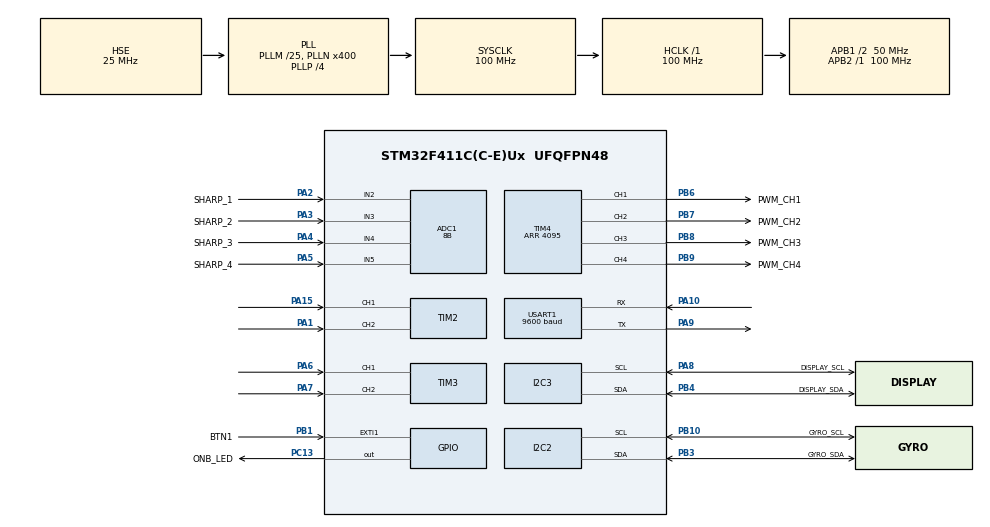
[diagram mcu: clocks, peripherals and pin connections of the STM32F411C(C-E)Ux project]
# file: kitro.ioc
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ADC1.Channel-1\#ChannelRegularConversion=ADC_CHANNEL_2
ADC1.ContinuousConvMode=DISABLE
ADC1.DMAContinuousRequests=ENABLE
ADC1.NbrOfConversion=1
ADC1.NbrOfConversionFlag=1
ADC1.Rank-1\#ChannelRegularConversion=1
ADC1.Resolution=ADC_RESOLUTION_8B
ADC1.SamplingTime-1\#ChannelRegularConversion=ADC_SAMPLETIME_3CYCLES
ADC1.master=1
Dma.ADC1.0.Direction=DMA_PERIPH_TO_MEMORY
Dma.ADC1.0.FIFOMode=DMA_FIFOMODE_DISABLE
Dma.ADC1.0.Instance=DMA2_Stream0
Dma.ADC1.0.MemDataAlignment=DMA_MDATAALIGN_HALFWORD
Dma.ADC1.0.MemInc=DMA_MINC_ENABLE
Dma.ADC1.0.Mode=DMA_CIRCULAR
Dma.ADC1.0.PeriphDataAlignment=DMA_PDATAALIGN_HALFWORD
Dma.ADC1.0.PeriphInc=DMA_PINC_DISABLE
Dma.ADC1.0.Priority=DMA_PRIORITY_LOW
Dma.Request0=ADC1
I2C3.I2C_Mode=I2C_Fast
Mcu.Family=STM32F4
Mcu.Name=STM32F411C(C-E)Ux
Mcu.Package=UFQFPN48
NVIC.DMA2_Stream0_IRQn=true\:0\:0\:false\:false\:true\:false\:true\:true
NVIC.EXTI1_IRQn=true\:0\:0\:false\:false\:true\:true\:true\:true
NVIC.PriorityGroup=NVIC_PRIORITYGROUP_4
NVIC.TIM1_TRG_COM_TIM11_IRQn=true\:0\:0\:false\:false\:true\:true\:true\:true
NVIC.TIM1_UP_TIM10_IRQn=true\:0\:0\:false\:false\:true\:true\:true\:true
NVIC.TIM5_IRQn=true\:0\:0\:false\:false\:true\:true\:true\:true
PA1.Signal=S_TIM2_CH2
PA10.Mode=Asynchronous
PA10.Signal=USART1_RX
PA15.Signal=S_TIM2_CH1_ETR
PA2.GPIO_Label=SHARP_1
PA2.Signal=ADCx_IN2
PA3.GPIO_Label=SHARP_2
PA3.Signal=ADCx_IN3
PA4.GPIO_Label=SHARP_3
PA4.Signal=ADCx_IN4
PA5.GPIO_Label=SHARP_4
PA5.Signal=ADCx_IN5
PA6.Signal=S_TIM3_CH1
PA7.Signal=S_TIM3_CH2
PA8.GPIO_Label=DISPLAY_SCL
PA8.Mode=I2C
PA8.Signal=I2C3_SCL
PA9.Mode=Asynchronous
PA9.Signal=USART1_TX
PB1.GPIO_Label=BTN1
PB1.GPIO_ModeDefaultEXTI=GPIO_MODE_IT_FALLING
PB1.GPIO_PuPd=GPIO_PULLDOWN
PB1.Signal=GPXTI1
PB10.GPIO_Label=GYRO_SCL
PB10.Mode=I2C
PB10.Signal=I2C2_SCL
PB3.GPIO_Label=GYRO_SDA
PB3.Mode=I2C
PB3.Signal=I2C2_SDA
PB4.GPIO_Label=DISPLAY_SDA
PB4.Mode=I2C
PB4.Signal=I2C3_SDA
PB6.GPIO_Label=PWM_CH1
PB6.Signal=S_TIM4_CH1
PB7.GPIO_Label=PWM_CH2
PB7.Signal=S_TIM4_CH2
PB8.GPIO_Label=PWM_CH3
PB8.Signal=S_TIM4_CH3
PB9.GPIO_Label=PWM_CH4
PB9.Signal=S_TIM4_CH4
PC13-ANTI_TAMP.GPIO_Label=ONB_LED
PC13-ANTI_TAMP.GPIO_PuPd=GPIO_NOPULL
PC13-ANTI_TAMP.Signal=GPIO_Output
PH0\ -\ OSC_IN.Mode=HSE-External-Oscillator
PH0\ -\ OSC_IN.Signal=RCC_OSC_IN
PH1\ -\ OSC_OUT.Mode=HSE-External-Oscillator
PH1\ -\ OSC_OUT.Signal=RCC_OSC_OUT
ProjectManager.HeapSize=0x200
ProjectManager.StackSize=0x400
ProjectManager.TargetToolchain=STM32CubeIDE
RCC.48MHZClocksFreq_Value=100000000
RCC.AHBFreq_Value=100000000
RCC.APB1CLKDivider=RCC_HCLK_DIV2
RCC.APB1Freq_Value=50000000
RCC.APB1TimFreq_Value=100000000
RCC.APB2Freq_Value=100000000
RCC.APB2TimFreq_Value=100000000
RCC.CortexFreq_Value=100000000
RCC.HCLKFreq_Value=100000000
RCC.HSE_VALUE=25000000
RCC.HSI_VALUE=16000000
RCC.LSE_VALUE=32768
RCC.PLLM=25
RCC.PLLN=400
RCC.PLLP=RCC_PLLP_DIV4
RCC.PLLSourceVirtual=RCC_PLLSOURCE_HSE
RCC.SYSCLKFreq_VALUE=100000000
RCC.SYSCLKSource=RCC_SYSCLKSOURCE_PLLCLK
RCC.VCOOutputFreq_Value=400000000
SH.ADCx_IN2.0=ADC1_IN2,IN2
SH.ADCx_IN3.0=ADC1_IN3,IN3
SH.ADCx_IN4.0=ADC1_IN4,IN4
SH.ADCx_IN5.0=ADC1_IN5,IN5
SH.S_TIM2_CH1_ETR.0=TIM2_CH1,Encoder_Interface
SH.S_TIM2_CH2.0=TIM2_CH2,Encoder_Interface
SH.S_TIM3_CH1.0=TIM3_CH1,Encoder_Interface
SH.S_TIM3_CH2.0=TIM3_CH2,Encoder_Interface
SH.S_TIM4_CH1.0=TIM4_CH1,PWM Generation1 CH1
SH.S_TIM4_CH2.0=TIM4_CH2,PWM Generation2 CH2
SH.S_TIM4_CH3.0=TIM4_CH3,PWM Generation3 CH3
SH.S_TIM4_CH4.0=TIM4_CH4,PWM Generation4 CH4
TIM10.Prescaler=15
TIM11.Prescaler=127
TIM4.Channel-PWM\ Generation1\ CH1=TIM_CHANNEL_1
TIM4.Channel-PWM\ Generation2\ CH2=TIM_CHANNEL_2
TIM4.Channel-PWM\ Generation3\ CH3=TIM_CHANNEL_3
TIM4.Channel-PWM\ Generation4\ CH4=TIM_CHANNEL_4
TIM4.Period=4095
USART1.BaudRate=9600
USART1.VirtualMode=VM_ASYNC
VP_ADC1_Vbat_Input.Mode=IN-Vbat
VP_TIM10_VS_ClockSourceINT.Mode=Enable_Timer
VP_TIM11_VS_ClockSourceINT.Mode=Enable_Timer
VP_TIM1_VS_ClockSourceINT.Mode=Internal
VP_TIM5_VS_ClockSourceINT.Mode=Internal
board=custom

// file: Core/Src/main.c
/* USER CODE BEGIN Header */
/**
 ******************************************************************************
 * @file           : main.c
 * @brief          : Main program body
 ******************************************************************************
 * @attention
 *
 * Copyright (c) 2024 STMicroelectronics.
 * All rights reserved.
 *
 * This software is licensed under terms that can be found in the LICENSE file
 * in the root directory of this software component.
 * If no LICENSE file comes with this software, it is provided AS-IS.
 *
 ******************************************************************************
 */
/* USER CODE END Header */
#include "main.h"

ADC_HandleTypeDef hadc1;
DMA_HandleTypeDef hdma_adc1;

I2C_HandleTypeDef hi2c2;
I2C_HandleTypeDef hi2c3;

TIM_HandleTypeDef htim1;
TIM_HandleTypeDef htim2;
TIM_HandleTypeDef htim3;
TIM_HandleTypeDef htim4;
TIM_HandleTypeDef htim5;
TIM_HandleTypeDef htim10;
TIM_HandleTypeDef htim11;

UART_HandleTypeDef huart1;

void SystemClock_Config(void);
static void MX_GPIO_Init(void);
static void MX_DMA_Init(void);
static void MX_ADC1_Init(void);
static void MX_I2C2_Init(void);
static void MX_I2C3_Init(void);
static void MX_TIM4_Init(void);
static void MX_USART1_UART_Init(void);
static void MX_TIM2_Init(void);
static void MX_TIM3_Init(void);
static void MX_TIM10_Init(void);
static void MX_TIM1_Init(void);
static void MX_TIM5_Init(void);
static void MX_TIM11_Init(void);
/* USER CODE BEGIN PFP */
//#define PUTCHAR_PROTOTYPE int __io_putchar(int ch)
/* USER CODE END PFP */

/* USER CODE BEGIN 0 */
int _write(int fd, char *ptr, int len) {
	HAL_UART_Transmit(&huart1, (uint8_t*) ptr, len, HAL_MAX_DELAY);
	return len;
}
/**
 * @brief  Retargets the C library printf function to the USART.
 *   None
 * @retval None
 */
//PUTCHAR_PROTOTYPE
//{
//  /* Place your implementation of fputc here */
//  /* e.g. write a character to the USART1 and Loop until the end of transmission */
//  HAL_UART_Transmit(&huart1, (uint8_t *)&ch, 1, 0xFFFF);
//
//  return ch;
//}
/* USER CODE END 0 */

int main(void)
{

  /* MCU Configuration--------------------------------------------------------*/

  /* Reset of all peripherals, Initializes the Flash interface and the Systick. */
  HAL_Init();

  /* Configure the system clock */
  SystemClock_Config();

  /* Initialize all configured peripherals */
  MX_GPIO_Init();
  MX_DMA_Init();
  MX_ADC1_Init();
  MX_I2C2_Init();
  MX_I2C3_Init();
  MX_TIM4_Init();
  MX_USART1_UART_Init();
  MX_TIM2_Init();
  MX_TIM3_Init();
  MX_TIM10_Init();
  MX_TIM1_Init();
  MX_TIM5_Init();
  MX_TIM11_Init();

  /* Infinite loop */
  /* USER CODE BEGIN WHILE */
	// transfer main to greymatter function in entry.cpp
	greymatter();
	while (1) {

    /* USER CODE END WHILE */

	}
}

void SystemClock_Config(void)
{
  RCC_OscInitTypeDef RCC_OscInitStruct = {0};
  RCC_ClkInitTypeDef RCC_ClkInitStruct = {0};

  /** Configure the main internal regulator output voltage
  */
  __HAL_RCC_PWR_CLK_ENABLE();
  __HAL_PWR_VOLTAGESCALING_CONFIG(PWR_REGULATOR_VOLTAGE_SCALE1);

  /** Initializes the RCC Oscillators according to the specified parameters
  * in the RCC_OscInitTypeDef structure.
  */
  RCC_OscInitStruct.OscillatorType = RCC_OSCILLATORTYPE_HSE;
  RCC_OscInitStruct.HSEState = RCC_HSE_ON;
  RCC_OscInitStruct.PLL.PLLState = RCC_PLL_ON;
  RCC_OscInitStruct.PLL.PLLSource = RCC_PLLSOURCE_HSE;
  RCC_OscInitStruct.PLL.PLLM = 25;
  RCC_OscInitStruct.PLL.PLLN = 400;
  RCC_OscInitStruct.PLL.PLLP = RCC_PLLP_DIV4;
  RCC_OscInitStruct.PLL.PLLQ = 4;
  if (HAL_RCC_OscConfig(&RCC_OscInitStruct) != HAL_OK)
  {
    Error_Handler();
  }

  /** Initializes the CPU, AHB and APB buses clocks
  */
  RCC_ClkInitStruct.ClockType = RCC_CLOCKTYPE_HCLK|RCC_CLOCKTYPE_SYSCLK
                              |RCC_CLOCKTYPE_PCLK1|RCC_CLOCKTYPE_PCLK2;
  RCC_ClkInitStruct.SYSCLKSource = RCC_SYSCLKSOURCE_PLLCLK;
  RCC_ClkInitStruct.AHBCLKDivider = RCC_SYSCLK_DIV1;
  RCC_ClkInitStruct.APB1CLKDivider = RCC_HCLK_DIV2;
  RCC_ClkInitStruct.APB2CLKDivider = RCC_HCLK_DIV1;

  if (HAL_RCC_ClockConfig(&RCC_ClkInitStruct, FLASH_LATENCY_3) != HAL_OK)
  {
    Error_Handler();
  }
}

static void MX_ADC1_Init(void)
{

  ADC_ChannelConfTypeDef sConfig = {0};

  /** Configure the global features of the ADC (Clock, Resolution, Data Alignment and number of conversion)
  */
  hadc1.Instance = ADC1;
  hadc1.Init.ClockPrescaler = ADC_CLOCK_SYNC_PCLK_DIV4;
  hadc1.Init.Resolution = ADC_RESOLUTION_8B;
  hadc1.Init.ScanConvMode = DISABLE;
  hadc1.Init.ContinuousConvMode = DISABLE;
  hadc1.Init.DiscontinuousConvMode = DISABLE;
  hadc1.Init.ExternalTrigConvEdge = ADC_EXTERNALTRIGCONVEDGE_NONE;
  hadc1.Init.ExternalTrigConv = ADC_SOFTWARE_START;
  hadc1.Init.DataAlign = ADC_DATAALIGN_RIGHT;
  hadc1.Init.NbrOfConversion = 1;
  hadc1.Init.DMAContinuousRequests = ENABLE;
  hadc1.Init.EOCSelection = ADC_EOC_SINGLE_CONV;
  if (HAL_ADC_Init(&hadc1) != HAL_OK)
  {
    Error_Handler();
  }

  /** Configure for the selected ADC regular channel its corresponding rank in the sequencer and its sample time.
  */
  sConfig.Channel = ADC_CHANNEL_2;
  sConfig.Rank = 1;
  sConfig.SamplingTime = ADC_SAMPLETIME_3CYCLES;
  if (HAL_ADC_ConfigChannel(&hadc1, &sConfig) != HAL_OK)
  {
    Error_Handler();
  }

}

static void MX_I2C2_Init(void)
{

  hi2c2.Instance = I2C2;
  hi2c2.Init.ClockSpeed = 100000;
  hi2c2.Init.DutyCycle = I2C_DUTYCYCLE_2;
  hi2c2.Init.OwnAddress1 = 0;
  hi2c2.Init.AddressingMode = I2C_ADDRESSINGMODE_7BIT;
  hi2c2.Init.DualAddressMode = I2C_DUALADDRESS_DISABLE;
  hi2c2.Init.OwnAddress2 = 0;
  hi2c2.Init.GeneralCallMode = I2C_GENERALCALL_DISABLE;
  hi2c2.Init.NoStretchMode = I2C_NOSTRETCH_DISABLE;
  if (HAL_I2C_Init(&hi2c2) != HAL_OK)
  {
    Error_Handler();
  }

}

static void MX_I2C3_Init(void)
{

  hi2c3.Instance = I2C3;
  hi2c3.Init.ClockSpeed = 400000;
  hi2c3.Init.DutyCycle = I2C_DUTYCYCLE_2;
  hi2c3.Init.OwnAddress1 = 0;
  hi2c3.Init.AddressingMode = I2C_ADDRESSINGMODE_7BIT;
  hi2c3.Init.DualAddressMode = I2C_DUALADDRESS_DISABLE;
  hi2c3.Init.OwnAddress2 = 0;
  hi2c3.Init.GeneralCallMode = I2C_GENERALCALL_DISABLE;
  hi2c3.Init.NoStretchMode = I2C_NOSTRETCH_DISABLE;
  if (HAL_I2C_Init(&hi2c3) != HAL_OK)
  {
    Error_Handler();
  }

}

static void MX_TIM1_Init(void)
{

  TIM_ClockConfigTypeDef sClockSourceConfig = {0};
  TIM_MasterConfigTypeDef sMasterConfig = {0};

  htim1.Instance = TIM1;
  htim1.Init.Prescaler = 0;
  htim1.Init.CounterMode = TIM_COUNTERMODE_UP;
  htim1.Init.Period = 65535;
  htim1.Init.ClockDivision = TIM_CLOCKDIVISION_DIV1;
  htim1.Init.RepetitionCounter = 0;
  htim1.Init.AutoReloadPreload = TIM_AUTORELOAD_PRELOAD_DISABLE;
  if (HAL_TIM_Base_Init(&htim1) != HAL_OK)
  {
    Error_Handler();
  }
  sClockSourceConfig.ClockSource = TIM_CLOCKSOURCE_INTERNAL;
  if (HAL_TIM_ConfigClockSource(&htim1, &sClockSourceConfig) != HAL_OK)
  {
    Error_Handler();
  }
  sMasterConfig.MasterOutputTrigger = TIM_TRGO_RESET;
  sMasterConfig.MasterSlaveMode = TIM_MASTERSLAVEMODE_DISABLE;
  if (HAL_TIMEx_MasterConfigSynchronization(&htim1, &sMasterConfig) != HAL_OK)
  {
    Error_Handler();
  }

}

static void MX_TIM2_Init(void)
{

  TIM_Encoder_InitTypeDef sConfig = {0};
  TIM_MasterConfigTypeDef sMasterConfig = {0};

  htim2.Instance = TIM2;
  htim2.Init.Prescaler = 0;
  htim2.Init.CounterMode = TIM_COUNTERMODE_UP;
  htim2.Init.Period = 4294967295;
  htim2.Init.ClockDivision = TIM_CLOCKDIVISION_DIV1;
  htim2.Init.AutoReloadPreload = TIM_AUTORELOAD_PRELOAD_DISABLE;
  sConfig.EncoderMode = TIM_ENCODERMODE_TI1;
  sConfig.IC1Polarity = TIM_ICPOLARITY_RISING;
  sConfig.IC1Selection = TIM_ICSELECTION_DIRECTTI;
  sConfig.IC1Prescaler = TIM_ICPSC_DIV1;
  sConfig.IC1Filter = 0;
  sConfig.IC2Polarity = TIM_ICPOLARITY_RISING;
  sConfig.IC2Selection = TIM_ICSELECTION_DIRECTTI;
  sConfig.IC2Prescaler = TIM_ICPSC_DIV1;
  sConfig.IC2Filter = 0;
  if (HAL_TIM_Encoder_Init(&htim2, &sConfig) != HAL_OK)
  {
    Error_Handler();
  }
  sMasterConfig.MasterOutputTrigger = TIM_TRGO_RESET;
  sMasterConfig.MasterSlaveMode = TIM_MASTERSLAVEMODE_DISABLE;
  if (HAL_TIMEx_MasterConfigSynchronization(&htim2, &sMasterConfig) != HAL_OK)
  {
    Error_Handler();
  }

}

static void MX_TIM3_Init(void)
{

  TIM_Encoder_InitTypeDef sConfig = {0};
  TIM_MasterConfigTypeDef sMasterConfig = {0};

  htim3.Instance = TIM3;
  htim3.Init.Prescaler = 0;
  htim3.Init.CounterMode = TIM_COUNTERMODE_UP;
  htim3.Init.Period = 65535;
  htim3.Init.ClockDivision = TIM_CLOCKDIVISION_DIV1;
  htim3.Init.AutoReloadPreload = TIM_AUTORELOAD_PRELOAD_DISABLE;
  sConfig.EncoderMode = TIM_ENCODERMODE_TI1;
  sConfig.IC1Polarity = TIM_ICPOLARITY_RISING;
  sConfig.IC1Selection = TIM_ICSELECTION_DIRECTTI;
  sConfig.IC1Prescaler = TIM_ICPSC_DIV1;
  sConfig.IC1Filter = 0;
  sConfig.IC2Polarity = TIM_ICPOLARITY_RISING;
  sConfig.IC2Selection = TIM_ICSELECTION_DIRECTTI;
  sConfig.IC2Prescaler = TIM_ICPSC_DIV1;
  sConfig.IC2Filter = 0;
  if (HAL_TIM_Encoder_Init(&htim3, &sConfig) != HAL_OK)
  {
    Error_Handler();
  }
  sMasterConfig.MasterOutputTrigger = TIM_TRGO_RESET;
  sMasterConfig.MasterSlaveMode = TIM_MASTERSLAVEMODE_DISABLE;
  if (HAL_TIMEx_MasterConfigSynchronization(&htim3, &sMasterConfig) != HAL_OK)
  {
    Error_Handler();
  }

}

static void MX_TIM4_Init(void)
{

  TIM_MasterConfigTypeDef sMasterConfig = {0};
  TIM_OC_InitTypeDef sConfigOC = {0};

  htim4.Instance = TIM4;
  htim4.Init.Prescaler = 0;
  htim4.Init.CounterMode = TIM_COUNTERMODE_UP;
  htim4.Init.Period = 4095;
  htim4.Init.ClockDivision = TIM_CLOCKDIVISION_DIV1;
  htim4.Init.AutoReloadPreload = TIM_AUTORELOAD_PRELOAD_DISABLE;
  if (HAL_TIM_PWM_Init(&htim4) != HAL_OK)
  {
    Error_Handler();
  }
  sMasterConfig.MasterOutputTrigger = TIM_TRGO_RESET;
  sMasterConfig.MasterSlaveMode = TIM_MASTERSLAVEMODE_DISABLE;
  if (HAL_TIMEx_MasterConfigSynchronization(&htim4, &sMasterConfig) != HAL_OK)
  {
    Error_Handler();
  }
  sConfigOC.OCMode = TIM_OCMODE_PWM1;
  sConfigOC.Pulse = 0;
  sConfigOC.OCPolarity = TIM_OCPOLARITY_HIGH;
  sConfigOC.OCFastMode = TIM_OCFAST_DISABLE;
  if (HAL_TIM_PWM_ConfigChannel(&htim4, &sConfigOC, TIM_CHANNEL_1) != HAL_OK)
  {
    Error_Handler();
  }
  if (HAL_TIM_PWM_ConfigChannel(&htim4, &sConfigOC, TIM_CHANNEL_2) != HAL_OK)
  {
    Error_Handler();
  }
  if (HAL_TIM_PWM_ConfigChannel(&htim4, &sConfigOC, TIM_CHANNEL_3) != HAL_OK)
  {
    Error_Handler();
  }
  if (HAL_TIM_PWM_ConfigChannel(&htim4, &sConfigOC, TIM_CHANNEL_4) != HAL_OK)
  {
    Error_Handler();
  }
  HAL_TIM_MspPostInit(&htim4);

}

static void MX_TIM5_Init(void)
{

  TIM_ClockConfigTypeDef sClockSourceConfig = {0};
  TIM_MasterConfigTypeDef sMasterConfig = {0};

  htim5.Instance = TIM5;
  htim5.Init.Prescaler = 0;
  htim5.Init.CounterMode = TIM_COUNTERMODE_UP;
  htim5.Init.Period = 4294967295;
  htim5.Init.ClockDivision = TIM_CLOCKDIVISION_DIV1;
  htim5.Init.AutoReloadPreload = TIM_AUTORELOAD_PRELOAD_DISABLE;
  if (HAL_TIM_Base_Init(&htim5) != HAL_OK)
  {
    Error_Handler();
  }
  sClockSourceConfig.ClockSource = TIM_CLOCKSOURCE_INTERNAL;
  if (HAL_TIM_ConfigClockSource(&htim5, &sClockSourceConfig) != HAL_OK)
  {
    Error_Handler();
  }
  sMasterConfig.MasterOutputTrigger = TIM_TRGO_RESET;
  sMasterConfig.MasterSlaveMode = TIM_MASTERSLAVEMODE_DISABLE;
  if (HAL_TIMEx_MasterConfigSynchronization(&htim5, &sMasterConfig) != HAL_OK)
  {
    Error_Handler();
  }

}

static void MX_TIM10_Init(void)
{

  htim10.Instance = TIM10;
  htim10.Init.Prescaler = 15;
  htim10.Init.CounterMode = TIM_COUNTERMODE_UP;
  htim10.Init.Period = 65535;
  htim10.Init.ClockDivision = TIM_CLOCKDIVISION_DIV1;
  htim10.Init.AutoReloadPreload = TIM_AUTORELOAD_PRELOAD_DISABLE;
  if (HAL_TIM_Base_Init(&htim10) != HAL_OK)
  {
    Error_Handler();
  }

}

static void MX_TIM11_Init(void)
{

  htim11.Instance = TIM11;
  htim11.Init.Prescaler = 127;
  htim11.Init.CounterMode = TIM_COUNTERMODE_UP;
  htim11.Init.Period = 65535;
  htim11.Init.ClockDivision = TIM_CLOCKDIVISION_DIV1;
  htim11.Init.AutoReloadPreload = TIM_AUTORELOAD_PRELOAD_DISABLE;
  if (HAL_TIM_Base_Init(&htim11) != HAL_OK)
  {
    Error_Handler();
  }

}

static void MX_USART1_UART_Init(void)
{

  huart1.Instance = USART1;
  huart1.Init.BaudRate = 9600;
  huart1.Init.WordLength = UART_WORDLENGTH_8B;
  huart1.Init.StopBits = UART_STOPBITS_1;
  huart1.Init.Parity = UART_PARITY_NONE;
  huart1.Init.Mode = UART_MODE_TX_RX;
  huart1.Init.HwFlowCtl = UART_HWCONTROL_NONE;
  huart1.Init.OverSampling = UART_OVERSAMPLING_16;
  if (HAL_UART_Init(&huart1) != HAL_OK)
  {
    Error_Handler();
  }

}

static void MX_DMA_Init(void)
{

  /* DMA controller clock enable */
  __HAL_RCC_DMA2_CLK_ENABLE();

  /* DMA interrupt init */
  /* DMA2_Stream0_IRQn interrupt configuration */
  HAL_NVIC_SetPriority(DMA2_Stream0_IRQn, 0, 0);
  HAL_NVIC_EnableIRQ(DMA2_Stream0_IRQn);

}

static void MX_GPIO_Init(void)
{
  GPIO_InitTypeDef GPIO_InitStruct = {0};

  /* GPIO Ports Clock Enable */
  __HAL_RCC_GPIOC_CLK_ENABLE();
  __HAL_RCC_GPIOH_CLK_ENABLE();
  __HAL_RCC_GPIOA_CLK_ENABLE();
  __HAL_RCC_GPIOB_CLK_ENABLE();

  /*Configure GPIO pin Output Level */
  HAL_GPIO_WritePin(ONB_LED_GPIO_Port, ONB_LED_Pin, GPIO_PIN_RESET);

  /*Configure GPIO pin : ONB_LED_Pin */
  GPIO_InitStruct.Pin = ONB_LED_Pin;
  GPIO_InitStruct.Mode = GPIO_MODE_OUTPUT_PP;
  GPIO_InitStruct.Pull = GPIO_NOPULL;
  GPIO_InitStruct.Speed = GPIO_SPEED_FREQ_LOW;
  HAL_GPIO_Init(ONB_LED_GPIO_Port, &GPIO_InitStruct);

  /*Configure GPIO pin : BTN1_Pin */
  GPIO_InitStruct.Pin = BTN1_Pin;
  GPIO_InitStruct.Mode = GPIO_MODE_IT_FALLING;
  GPIO_InitStruct.Pull = GPIO_PULLDOWN;
  HAL_GPIO_Init(BTN1_GPIO_Port, &GPIO_InitStruct);

  /* EXTI interrupt init*/
  HAL_NVIC_SetPriority(EXTI1_IRQn, 0, 0);
  HAL_NVIC_EnableIRQ(EXTI1_IRQn);

}

void Error_Handler(void)
{
	__disable_irq();
	while (1) {
	}
}
